# HR_C7000_DM32 register map
Vendor: Dahua Technology (chip); Baofeng (radio product); Series: HR_C7000; File version: 0.1-dm32re-draft
CPU: other r0p0, little endian, no MPU, no FPU, 0 interrupt priority bits
Registers are 32-bit, read-write, reset 0x0 unless marked. A register's access mark holds for its fields unless they carry their own. Offsets are from the block's base; [hi:lo] are bit positions; {n}, {i} and the like mark numbered series.

## SPI_Master0 — SPI master 0, Synopsys DesignWare APB SSI (DS §5.2, p.243-264; FIFO depth 128). On the DM-32 this is the bus to the 16 MB W25Q128 data flash (chip-select 0x12) holding the codeplug and per-unit calibration (QEMU: dm32uv-qemu dm32_ssi; Winbond W25Q128JV datasheet). FW: first entry of the SSI driver's base table at 0x030ada00 = {SPI_Master0, SPI_Master1, SPI2, SPI_Master3, 0x04000000}, plus 4 direct sites.
Base 0x140A0000
Same registers: SPI_Master1 0x140B0000, SPI2 0x140E0000, SPI_Slave0 0x14120000, SPI_Slave1 0x14130000, SPI_Slave2 0x14140000, SPI_Master3 0x14150000
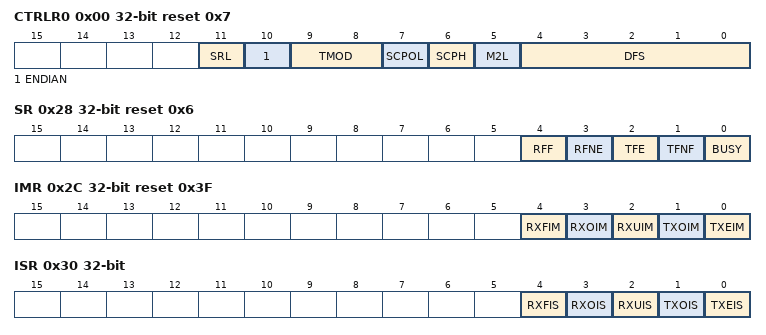
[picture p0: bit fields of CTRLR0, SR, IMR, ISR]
0x00 CTRLR0 reset 0x7 — Transmission mode and frame length. DS §5.2.5.1 p.254. The datasheet gives master and slave interpretations of bits [10] and [5:0] in one table; the master view is used for the field list, the slave view is recorded in each field's description. Reset 0x7 (DS).
  [11] SRL — Self-loop (loopback) test mode [reset 0x0] [access RW]
  [10] ENDIAN — Master: endian control, 1: big endian; 0: little endian. Slave view of this bit: SLV_OE, slave txd output enable (0: enable; 1: disable). Printed as 'e ENDING (as master)' [reset 0x0] [access RW]
  [9:8] TMOD — Transfer mode. 00: transmit & receive; 01: transmit only; 10: receive only; 11: EEPROM read (master only) [reset 0x0] [access RW]
  [7] SCPOL — Clock polarity: level of SCLK when inactive [reset 0x0] [access RW]
  [6] SCPH — Clock phase. 0: sample on first SCLK edge; 1: on second edge [reset 0x0] [access RW]
  [5] M2L — Bit order. 0: MSB first; 1: LSB first. Slave view of [5:4]: FRF, serial protocol, 00 = Motorola SPI (fixed) [reset 0x0] [access RW]
  [4:0] DFS — Data frame size (frame length - 1). Slave view: DFS is [3:0], reset 0x7 [reset 0x7] [access RW]
0x04 CTRLR1 — Number of received data frames. DS §5.2.5.2 p.256. Reset 0x0 (DS).
  [15:0] NDF — Number of data received [reset 0x0] [access RW]
0x08 SSIENR — SPI module enable. DS §5.2.5.3 p.256. FW: 0 reads, 1 write. Reset 0x0 (DS).
  [0] SSI_EN — SPI module enable, disable configuration register when 1 , clear FIFO when 0 and status register [reset 0x0] [access RW]
0x10 SER — slave Chip select enable. DS §5.2.5.4 p.256. Reset 0x0 (DS).
  [1:0] SER — slave chip select [reset 0x0] [access RW]
0x14 BAUDR — Clock enable and frequency division. DS §5.2.5.5 p.256. Reset 0x0 (DS).
  [15:0] SCKDV — SCLK divider: f_sclk = f_ssi_clk / SCKDV. Only even values allowed; 0 disables the serial clock (this row is printed in Chinese in the English edition: 输出时钟分频，只允许偶数分频，为0时禁用时钟) [reset 0x0] [access RW]
0x18 TXFTLR — Transmit FIFO threshold. DS §5.2.5.6 p.258. FW: 0 reads, 1 write. Reset 0x0 (DS).
  [7:0] TFT — Transmit data FIFO threshold [reset 0x0] [access RW]
0x1C RXFTLR — Receive FIFO threshold. DS §5.2.5.7 p.258. FW: 0 reads, 1 write. Reset 0x0 (DS).
  [7:0] RFT — Receive data FIFO threshold [reset 0x0] [access RW]
0x20 TXFLR ro — Number of data in the transmit FIFO. DS §5.2.5.8 p.258. Reset 0x0 (DS).
  [7:0] TXTFL — Number of data in the transmit data FIFO [reset 0x0] [access RO]
0x24 RXFLR ro — Number of data in receive FIFO. DS §5.2.5.9 p.258. Reset 0x0 (DS).
  [7:0] RXTFL — Number of data in the receive data FIFO [reset 0x0] [access RO]
0x28 SR ro reset 0x6 — SPI module status. DS §5.2.5.10 p.258. Reset 0x6 (DS).
  [4] RFF — Receive fifo is full. 0 : not full; 1 : full [reset 0x0] [access RO]
  [3] RFNE — Receive FIFO is not empty. 0 : empty; 1 : not empty [reset 0x0] [access RO]
  [2] TFE — Transmit FIFO is empty. 0 : Not empty; 1 : Empty [reset 0x1] [access RO]
  [1] TFNF — Transmit FIFO is not full. 0 : full; 1 : not full [reset 0x1] [access RO]
  [0] BUSY — Transferring data [reset 0x0] [access RO]
0x2C IMR reset 0x3F — Interrupt mask register. DS §5.2.5.11 p.260. FW: 0 reads, 1 write. Reset 0x3f (DS).
  [4] RXFIM — Receive data exceeds threshold interrupt mask [reset 0x1] [access RW]
  [3] RXOIM — Receive FIFO Overflow interrupt shield [reset 0x1] [access RW]
  [2] RXUIM — Receive FIFO underflow interrupt shield [reset 0x1] [access RW]
  [1] TXOIM — Transmit FIFO Overflow interrupt shield [reset 0x1] [access RW]
  [0] TXEIM — Transmit FIFO Null interrupt mask [reset 0x1] [access RW]
0x30 ISR ro — Masked interrupt register. DS §5.2.5.12 p.260. Reset 0x0 (DS).
  [4] RXFIS — Masked receive data exceeds threshold interrupt [reset 0x0] [access RO]
  [3] RXOIS — Masked receive FIFO overflow interrupt [reset 0x0] [access RO]
  [2] RXUIS — Masked receive FIFO underflow interrupt [reset 0x0] [access RO]
  [1] TXOIS — Masked transmit FIFO overflow interrupt [reset 0x0] [access RO]
  [0] TXEIS — Masked transmit FIFO Empty Interrupt [reset 0x0] [access RO]
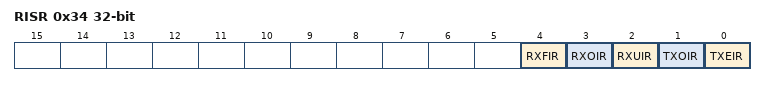
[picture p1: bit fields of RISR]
0x34 RISR ro — Unmasked interrupt register. DS §5.2.5.13 p.260. Reset 0x0 (DS).
  [4] RXFIR — Unmasked receive data exceeds threshold interrupt [reset 0x0] [access RO]
  [3] RXOIR — Unmasked receive FIFO overflow interrupt [reset 0x0] [access RO]
  [2] RXUIR — Unmasked receive FIFO underflow interrupt [reset 0x0] [access RO]
  [1] TXOIR — Unmasked transmit FIFO overflow interrupt [reset 0x0] [access RO]
  [0] TXEIR — Unmasked transmit FIFO Empty Interrupt [reset 0x0] [access RO]
0x38 TXOICR ro — Transmit FIFO overflow Interrupt clear. DS §5.2.5.14 p.260. Reset 0x0 (DS).
  [0] TXOICR — Clear transmit FIFO overflow interrupt [reset 0x0] [access RO]
0x3C RXOICR ro — Receive FIFO overflow Interrupt clear. DS §5.2.5.15 p.262. Reset 0x0 (DS).
  [0] RXOICR — Clear receive FIFO overflow interrupt [reset 0x0] [access RO]
0x40 RXUICR ro — Receive FIFO underflow Interrupt clear. DS §5.2.5.16 p.262. Reset 0x0 (DS).
  [0] RXUICR — Clear receive FIFO underflow interrupt [reset 0x0] [access RO]
0x48 ICR ro — Clear ssi_txo_intr , ssi_rxu_intr , ssi_rxo_intr. DS §5.2.5.17 p.262. Reset 0x0 (DS).
  [0] ICR — Clear transmit FIFO Overflow interrupt, receive FIFO overflow interrupt, Receive FIFO underflow interrupt [reset 0x0] [access RO]
0x58 IDR ro reset 0x11223344 — Module ID Register. DS §5.2.5.18 p.262. Reset 0x11223344 (DS).
  [31:0] IDR — Module ID [reset 0x11223344] [access RO]
0x5C SSI_COMP_VERSION ro reset 0x3331312A — Version number. DS §5.2.5.19 p.262. Reset 0x3331312a (DS).
  [31:0] SSI_COMP_VERSION — Module version number [reset 0x3331312a] [access RO]
0x60 DR — Data transmit / receive FIFO interface. DS §5.2.5.20 p.263. Printed RO in the datasheet, but it is the TX/RX FIFO data port and the stock firmware writes it (FW: SPI_Master3 +0x60 read 1, write 1). Reset 0x0 (DS).
  [31:0] DR — FIFO read / write address [reset 0x0] [access RW]
